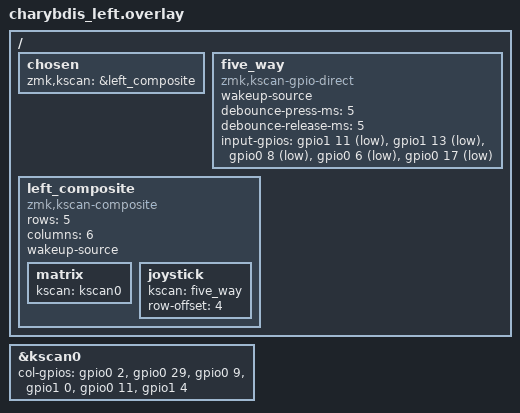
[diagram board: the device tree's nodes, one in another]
/*
 * Copyright (c) 2020 ZMK Contributors
 *
 * SPDX-License-Identifier: MIT
 */

#include "charybdis.dtsi"

&kscan0 {
	col-gpios
		= <&gpio0 2 (GPIO_ACTIVE_HIGH | GPIO_PULL_DOWN)>
		, <&gpio0 29 (GPIO_ACTIVE_HIGH | GPIO_PULL_DOWN)>
		, <&gpio0 9 (GPIO_ACTIVE_HIGH | GPIO_PULL_DOWN)>
		, <&gpio1 0  (GPIO_ACTIVE_HIGH | GPIO_PULL_DOWN)>
		, <&gpio0 11 (GPIO_ACTIVE_HIGH | GPIO_PULL_DOWN)>
		, <&gpio1 4  (GPIO_ACTIVE_HIGH | GPIO_PULL_DOWN)>
		;
};

//RGB bus



/ {
    chosen {
        zmk,kscan = &left_composite;
    };

    five_way: five_way {
        compatible = "zmk,kscan-gpio-direct";
        wakeup-source;
        debounce-press-ms = <5>;
        debounce-release-ms = <5>;
        /* UP, DOWN, LEFT, RIGHT, CENTER; each switch closes to GND. */
        input-gpios = <&gpio1 11 (GPIO_ACTIVE_LOW | GPIO_PULL_UP)>,
                      <&gpio1 13 (GPIO_ACTIVE_LOW | GPIO_PULL_UP)>,
                      <&gpio0 8  (GPIO_ACTIVE_LOW | GPIO_PULL_UP)>,
                      <&gpio0 6  (GPIO_ACTIVE_LOW | GPIO_PULL_UP)>,
                      <&gpio0 17 (GPIO_ACTIVE_LOW | GPIO_PULL_UP)>;
    };

    left_composite: left_composite {
        compatible = "zmk,kscan-composite";
        rows = <5>;
        columns = <6>;
        wakeup-source;

        matrix {
            kscan = <&kscan0>;
        };
        joystick {
            kscan = <&five_way>;
            row-offset = <4>;
        };
    };
};
